# AVR32SD28 device description
Architecture: AVR8X; Family: AVR
Registers are 8-bit, read-write, reset 0x0 unless marked. A register's access mark holds for its fields unless they carry their own. Offsets are from the block's base; [hi:lo] are bit positions; {n}, {i} and the like mark numbered series; 'fields as' and 'values as' point back to an identical list; <NAME> marks a mode.

## USART — Universal Synchronous and Asynchronous Receiver and Transmitter
Instances: USART0 0x0800, USART1 0x0820, USART2 0x0840
0x00 RXDATAL ro — Receive Data Low Byte
  [7:0] DATA — RX Data
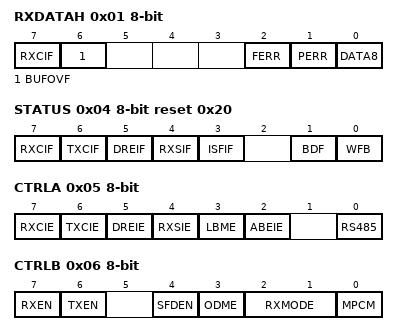
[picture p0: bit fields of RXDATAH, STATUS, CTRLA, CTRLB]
0x01 RXDATAH ro — Receive Data High Byte
  [7] RXCIF — Receive Complete Interrupt Flag
  [6] BUFOVF — Buffer Overflow
  [2] FERR — Frame Error
  [1] PERR — Parity Error
  [0] DATA8 — Receiver Data Register
0x02 TXDATAL — Transmit Data Low Byte
  [7:0] DATA — Transmit Data Register
0x03 TXDATAH — Transmit Data High Byte
  [0] DATA8 — Transmit Data Register (CHSIZE=9bit)
0x04 STATUS reset 0x20
  [7] RXCIF ro — Receive Complete Interrupt Flag
  [6] TXCIF — Transmit Interrupt Flag
  [5] DREIF ro — Data Register Empty Flag
  [4] RXSIF — Receive Start Interrupt
  [3] ISFIF — Inconsistent Sync Field Interrupt Flag
  [1] BDF — Break Detected Flag
  [0] WFB wo — Wait For Break
0x05 CTRLA — Control A
  [7] RXCIE — Receive Complete Interrupt Enable
  [6] TXCIE — Transmit Complete Interrupt Enable
  [5] DREIE — Data Register Empty Interrupt Enable
  [4] RXSIE — Receiver Start Frame Interrupt Enable
  [3] LBME — Loop-back Mode Enable
  [2] ABEIE — Auto-baud Error Interrupt Enable
  [0] RS485 — RS485 Mode internal transmitter
    0=DISABLE (RS485 Mode disabled); 1=ENABLE (RS485 Mode enabled)
0x06 CTRLB — Control B
  [7] RXEN — Reciever enable
  [6] TXEN — Transmitter Enable
  [4] SFDEN — Start Frame Detection Enable
  [3] ODME — Open Drain Mode Enable
  [2:1] RXMODE — Receiver Mode
    0=NORMAL (Normal mode); 1=CLK2X (CLK2x mode); 2=GENAUTO (Generic autobaud mode); 3=LINAUTO (LIN constrained autobaud mode)
  [0] MPCM — Multi-processor Communication Mode
0x07 CTRLC reset 0x3 (modes: NORMAL when USART.CTRLC.CMODE=0x00 0x01 0x02; MSPI when USART.CTRLC.CMODE=0x03) — Control C
  [7:6] CMODE — Communication Mode
    0=ASYNCHRONOUS (Asynchronous Mode); 1=SYNCHRONOUS (Synchronous Mode); 2=IRCOM (Infrared Communication); 3=MSPI (SPI Host Mode)
  [2] UDORD <MSPI> — SPI Host Mode, Data Order
  [1] UCPHA <MSPI> — SPI Host Mode, Clock Phase
  [5:4] PMODE <NORMAL> — Parity Mode
    0=DISABLED (No Parity); 2=EVEN (Even Parity); 3=ODD (Odd Parity)
  [3] SBMODE <NORMAL> — Stop Bit Mode
    0=1BIT (1 stop bit); 1=2BIT (2 stop bits)
  [2:0] CHSIZE <NORMAL> — Character Size
    {v}={v+5}BIT (Character size: {v+5} bit) (v=0..3); 6=9BITL (Character size: 9 bit read low byte first); 7=9BITH (Character size: 9 bit read high byte first)
0x08 BAUD 16-bit — Baud Rate
0x0A CTRLD — Control D
  [7:6] ABW — Auto Baud Window
    0=WDW0 (18% tolerance); 1=WDW1 (15% tolerance); 2=WDW2 (21% tolerance); 3=WDW3 (25% tolerance)
0x0B DBGCTRL — Debug Control
  [0] DBGRUN — Debug Run
0x0C EVCTRL — Event Control
  [0] IREI — IrDA Event Input Enable
0x0D TXPLCTRL — IRCOM Transmitter Pulse Length Control
  [7:0] TXPL — Transmit pulse length
0x0E RXPLCTRL — IRCOM Receiver Pulse Length Control
  [6:0] RXPL — Receiver Pulse Lenght

## USERROW
Instances: USERROW 0x1200
{0x0+i} USERROW[{i}] (i=0..511) reset not defined

## VPORT — Virtual Ports
Instances: VPORTA 0x0000, VPORTC 0x0008, VPORTD 0x000C, VPORTF 0x0014
0x00 DIR — Data Direction
0x01 OUT — Output Value
0x02 IN — Input Value
0x03 INTFLAGS — Interrupt Flags
  [7:0] INT — Pin Interrupt Flag

## VREF — Voltage Reference
Instances: VREF 0x0070
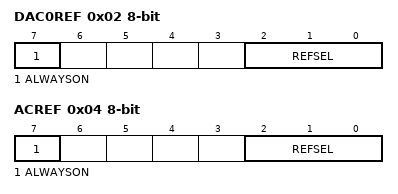
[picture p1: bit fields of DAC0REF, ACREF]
0x02 DAC0REF — DAC0 Reference
  [7] ALWAYSON
  [2:0] REFSEL — Reference select
    0=1V024 (Internal 1.024V reference); 1=2V048 (Internal 2.048V reference); 2=4V096 (Internal 4.096V reference); 3=2V500 (Internal 2.500V reference); 5=VDD (VDD as reference); 6=VREFA (External reference on VREFA pin)
0x04 ACREF — AC Reference
  fields as DAC0REF

## WDT — Watchdog Timer
Instances: WDT 0x0110
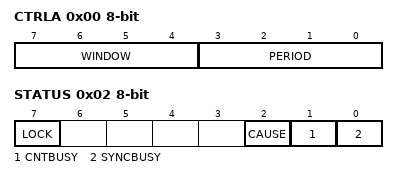
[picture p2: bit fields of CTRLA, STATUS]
0x00 CTRLA reset not defined — Control A
  [7:4] WINDOW
    0=OFF; 1=8CLK (8 cycles (244 us)); 2=16CLK (16 cycles (488 us)); 3=32CLK (32 cycles (976 us)); 4=64CLK (64 cycles (1.95 ms)); 5=128CLK (128 cycles (3.9 ms)); 6=256CLK (256 cycles (7.8 ms)); 7=512CLK (512 cycles (15.625 ms)); 8=1KCLK (1K cycles (31.25 ms)); 9=2KCLK (2K cycles (62.5 ms)); 10=4KCLK (4K cycles (125 ms)); 11=8KCLK (8K cycles (250 ms))
  [3:0] PERIOD
    values as WINDOW
0x01 CTRLB ro reset 0x40 — Control B
  [7:6] WDTMON — WDT Clock Monitor
    0=OFF (Monitor is disabled); 1=ON (Monitor is always on); 2=SLEEP (Monitor is always on in normal and IDLE mode, but automatically disabled when the MCU is in POWERDOWN and STANDBY sleep modes)
0x02 STATUS
  [7] LOCK — Lock enable
  [2] CAUSE ro — Reset Cause
    0=OUTSIDE (Outside window); 1=TIMEOUT
  [1] CNTBUSY ro — CNT Synchronization Busy
  [0] SYNCBUSY ro — Syncronization busy
0x04 CNT 16-bit ro — Counter
  [13:0] CNT

## ZCD — Zero Cross Detect
Instances: ZCD0 0x06C0, ZCD3 0x06D8
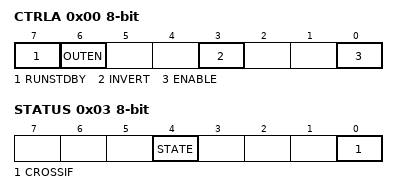
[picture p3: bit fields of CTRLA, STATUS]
0x00 CTRLA — Control A
  [7] RUNSTDBY — Run in Standby Mode
  [6] OUTEN — Output Pad Enable
  [3] INVERT — Invert signal from pin
  [0] ENABLE
0x02 INTCTRL — Interrupt Control
  [1:0] INTMODE — Interrupt Mode
    0=NONE (No interrupt); 1=RISING (Interrupt on rising input signal); 2=FALLING (Interrupt on falling input signal); 3=BOTH (Interrupt on both rising and falling input signal)
0x03 STATUS
  [4] STATE ro — ZCD State
    0=LOW (Output is 0); 1=HIGH (Output is 1)
  [0] CROSSIF — ZCD Interrupt Flag
